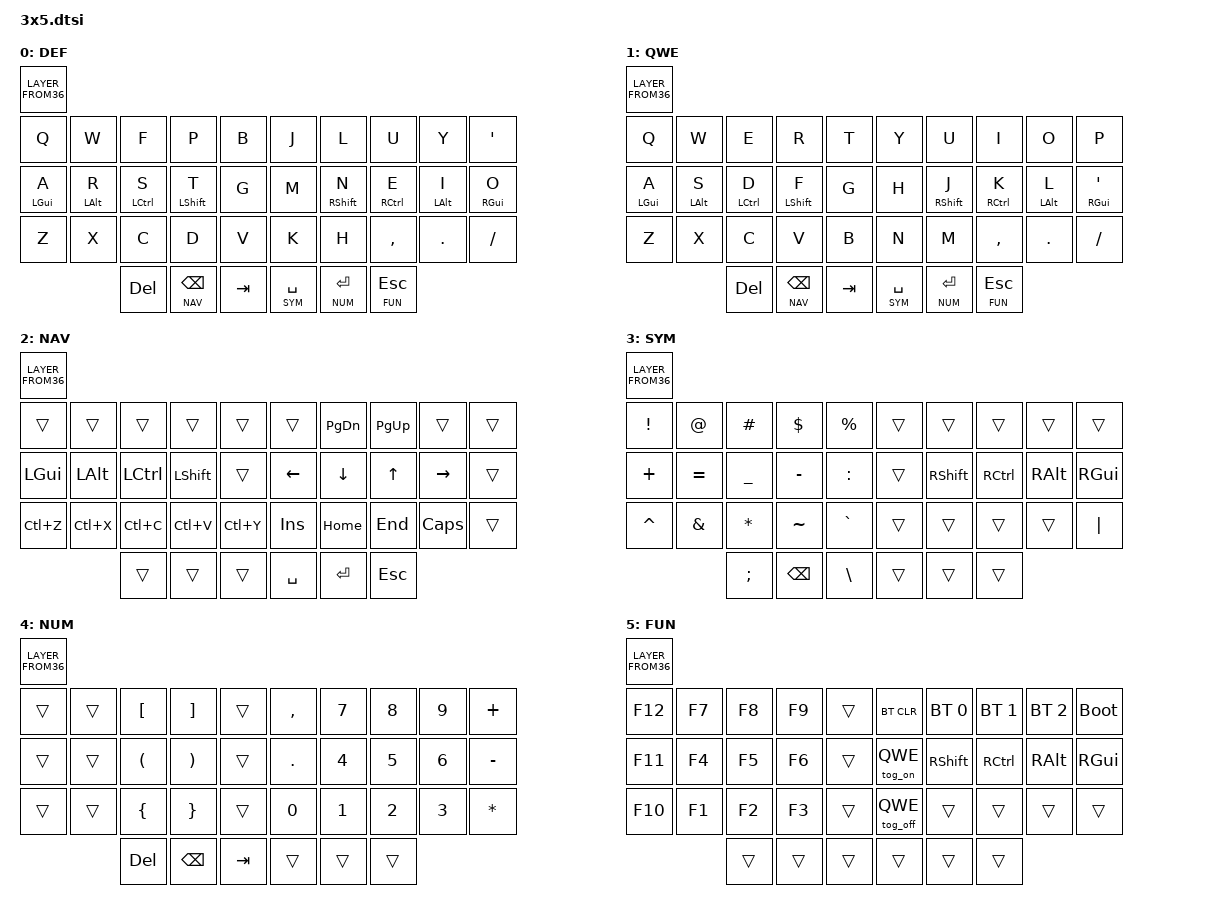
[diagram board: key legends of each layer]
#include <behaviors.dtsi>
#include <dt-bindings/zmk/bt.h>
#include <dt-bindings/zmk/keys.h>  
#include <dt-bindings/zmk/bt.h>
#include <dt-bindings/zmk/outputs.h>

// #include "combos.dtsi"
// #include "mouse.dtsi"

#define DEF 0
#define QWE 1
#define NAV 2
#define SYM 3
#define NUM 4
#define FUN 5   

#define XXX &none
#define ___ &trans

&caps_word {
    continue-list = <UNDERSCORE MINUS BSPC DEL N1 N2 N3 N4 N5 N6 N7 N8 N9 N0>;
};

/ {
  behaviors {
    hml: home_row_mods_l {
      compatible = "zmk,behavior-hold-tap";
      #binding-cells = <2>;
      tapping-term-ms = <250>;
      quick-tap-ms = <150>;
      flavor = "balanced";
      bindings = <&kp>, <&kp>;
      hold-trigger-key-positions = <KEYS_R THUMBS>;
      hold-trigger-on-release;
      require-prior-idle-ms = <175>;
    };
    hmr: home_row_mods_r {
      compatible = "zmk,behavior-hold-tap";
      #binding-cells = <2>;
      tapping-term-ms = <250>;
      quick-tap-ms = <150>;
      flavor = "balanced";
      bindings = <&kp>, <&kp>;
      hold-trigger-key-positions = <KEYS_L THUMBS>;
      hold-trigger-on-release;
      require-prior-idle-ms = <175>;
    };
    lt: layer_tap {
      display-name = "Layer-Tap";
      compatible = "zmk,behavior-hold-tap";
      #binding-cells = <2>;
      tapping-term-ms = <150>;
      flavor = "balanced"; // <- maybe tap-preferred
      bindings = <&mo>, <&kp>;
    };        
    mt: mod_tap {
      compatible = "zmk,behavior-hold-tap";
      #binding-cells = <2>;
      flavor = "hold-preferred";
      tapping-term-ms = <150>;
      bindings = <&kp>, <&kp>;
      display-name = "Mod-Tap";
    };
    tog_on: toggle_layer_on_only {
      display-name = "Toggle Layer On";
      compatible = "zmk,behavior-toggle-layer";
      #binding-cells = <1>;
      toggle-mode = "on";
    };
    tog_off: toggle_layer_off_only {
      display-name = "Toggle Layer Off";
      compatible = "zmk,behavior-toggle-layer";
      #binding-cells = <1>;
      toggle-mode = "off";
    };
  };

  keymap {
    compatible = "zmk,keymap";

    default_layer {
      display-name = "DEF";
      bindings = <LAYER_FROM36( \
// ╭─────────────┬─────────────┬─────────────┬─────────────┬─────────────╮   ╭─────────────┬─────────────┬─────────────┬─────────────┬─────────────╮
     &kp Q,        &kp W,        &kp F,        &kp P,        &kp B,            &kp J,        &kp L,        &kp U,        &kp Y,        &kp SQT,      \
// ├─────────────┼─────────────┼─────────────┼─────────────┼─────────────┤   ├─────────────┼─────────────┼─────────────┼─────────────┼─────────────┤
     &hml LGUI A,  &hml LALT R,  &hml LCTRL S, &hml LSHFT T, &kp G,            &kp M,        &hmr RSHFT N, &hmr RCTRL E, &hmr LALT I,  &hmr RGUI O,  \
// ├─────────────┼─────────────┼─────────────┼─────────────┼─────────────┤   ├─────────────┼─────────────┼─────────────┼─────────────┼─────────────┤
     &kp Z,        &kp X,        &kp C,        &kp D,        &kp V,            &kp K,        &kp H,        &kp COMMA,    &kp DOT,      &kp SLASH,    \
// ╰─────────────┴─────────────┴─────────────┼─────────────┼─────────────┤   ├─────────────┼─────────────┼─────────────┴─────────────┴─────────────╯
                                 &kp DEL,      &lt NAV BSPC, &kp TAB,          &lt SYM SPACE,&lt NUM RET,  &lt FUN ESC  
//                             ╰─────────────┴─────────────┴─────────────╯   ╰─────────────┴─────────────┴─────────────╯
      )>;
    };

    qwerty_layer {
      display-name = "QWE";
      bindings = <LAYER_FROM36( \
// ╭─────────────┬─────────────┬─────────────┬─────────────┬─────────────╮   ╭─────────────┬─────────────┬─────────────┬─────────────┬─────────────╮
     &kp Q,        &kp W,        &kp E,        &kp R,        &kp T,            &kp Y,        &kp U,        &kp I,        &kp O,        &kp P,        \
// ├─────────────┼─────────────┼─────────────┼─────────────┼─────────────┤   ├─────────────┼─────────────┼─────────────┼─────────────┼─────────────┤
     &hml LGUI A,  &hml LALT S,  &hml LCTRL D, &hml LSHFT F, &kp G,            &kp H,        &hmr RSHFT J, &hmr RCTRL K, &hmr LALT L,  &hmr RGUI SQT, \
// ├─────────────┼─────────────┼─────────────┼─────────────┼─────────────┤   ├─────────────┼─────────────┼─────────────┼─────────────┼─────────────┤
     &kp Z,        &kp X,        &kp C,        &kp V,        &kp B,            &kp N,        &kp M,        &kp COMMA,    &kp DOT,      &kp FSLH,     \
// ╰─────────────┴─────────────┴─────────────┼─────────────┼─────────────┤   ├─────────────┼─────────────┼─────────────┴─────────────┴─────────────╯
                                 &kp DEL,      &lt NAV BSPC, &kp TAB,          &lt SYM SPACE,&lt NUM RET,  &lt FUN ESC  
//                             ╰─────────────┴─────────────┴─────────────╯   ╰─────────────┴─────────────┴─────────────╯
      )>;      
    };

    nav_layer {
      display-name = "NAV";
      bindings = <LAYER_FROM36( \
// ╭─────────────┬─────────────┬─────────────┬─────────────┬─────────────╮   ╭─────────────┬─────────────┬─────────────┬─────────────┬─────────────╮
     ___,          ___,          ___,          ___,          ___,              ___,          &kp PG_DN,    &kp PG_UP,    ___,          ___,          \
// ├─────────────┼─────────────┼─────────────┼─────────────┼─────────────┤   ├─────────────┼─────────────┼─────────────┼─────────────┼─────────────┤
     &kp LGUI,     &kp LALT,     &kp LCTRL,    &kp LSHFT,    ___,              &kp LEFT,     &kp DOWN,     &kp UP,       &kp RIGHT,    ___,          \
// ├─────────────┼─────────────┼─────────────┼─────────────┼─────────────┤   ├─────────────┼─────────────┼─────────────┼─────────────┼─────────────┤
     &kp LC(Z),    &kp LC(X),    &kp LC(C),    &kp LC(V),    &kp LC(Y),        &kp INS,      &kp HOME,     &kp END,      &kp CAPS,     ___,          \
// ╰─────────────┴─────────────┴─────────────┼─────────────┼─────────────┤   ├─────────────┼─────────────┼─────────────┴─────────────┴─────────────╯
                                 ___,          ___,          ___,              &kp SPACE,    &kp RET,      &kp ESC
//                             ╰─────────────┴─────────────┴─────────────╯   ╰─────────────┴─────────────┴─────────────╯
      )>;
    };

    symbol_layer {
      display-name = "SYM";
      bindings = <LAYER_FROM36( \
// ╭─────────────┬─────────────┬─────────────┬─────────────┬─────────────╮   ╭─────────────┬─────────────┬─────────────┬─────────────┬─────────────╮
     &kp EXCL,     &kp AT,       &kp HASH,     &kp DLLR,     &kp PRCNT,        ___,          ___,          ___,          ___,          ___,          \
// ├─────────────┼─────────────┼─────────────┼─────────────┼─────────────┤   ├─────────────┼─────────────┼─────────────┼─────────────┼─────────────┤
     &kp PLUS,     &kp EQUAL,    &kp UNDER,    &kp MINUS,    &kp COLON,        ___,          &kp RSHFT,    &kp RCTRL,    &kp RALT,     &kp RGUI,     \
// ├─────────────┼─────────────┼─────────────┼─────────────┼─────────────┤   ├─────────────┼─────────────┼─────────────┼─────────────┼─────────────┤
     &kp CARET,    &kp AMPS,     &kp STAR,     &kp TILDE,    &kp GRAVE,        ___,          ___,          ___,          ___,          &kp PIPE,     \
// ╰─────────────┴─────────────┴─────────────┼─────────────┼─────────────┤   ├─────────────┼─────────────┼─────────────┴─────────────┴─────────────╯
                                 &kp SEMI,     &kp BSPC,     &kp BSLH,         ___,          ___,          ___
//                             ╰─────────────┴─────────────┴─────────────╯   ╰─────────────┴─────────────┴─────────────╯
      )>;
    };

    num_layer {
      display-name = "NUM";
      bindings = <LAYER_FROM36( \
// ╭─────────────┬─────────────┬─────────────┬─────────────┬─────────────╮   ╭─────────────┬─────────────┬─────────────┬─────────────┬─────────────╮
     ___,          ___,          &kp LBKT,     &kp RBKT,     ___,              &kp COMMA,    &kp N7,       &kp N8,       &kp N9,       &kp PLUS,     \
// ├─────────────┼─────────────┼─────────────┼─────────────┼─────────────┤   ├─────────────┼─────────────┼─────────────┼─────────────┼─────────────┤
     ___,          ___,          &kp LPAR,     &kp RPAR,     ___,              &kp DOT,      &kp N4,       &kp N5,       &kp N6,       &kp MINUS,    \
// ├─────────────┼─────────────┼─────────────┼─────────────┼─────────────┤   ├─────────────┼─────────────┼─────────────┼─────────────┼─────────────┤
     ___,          ___,          &kp LBRC,     &kp RBRC,     ___,              &kp N0,       &kp N1,       &kp N2,       &kp N3,       &kp STAR,     \
// ╰─────────────┴─────────────┴─────────────┼─────────────┼─────────────┤   ├─────────────┼─────────────┼─────────────┴─────────────┴─────────────╯
                                 &kp DEL,      &kp BSPC,     &kp TAB,          ___,          ___,          ___
//                             ╰─────────────┴─────────────┴─────────────╯   ╰─────────────┴─────────────┴─────────────╯
      )>;
    };

    fun_layer {
      display-name = "FUN";
      bindings = <LAYER_FROM36( \
// ╭─────────────┬─────────────┬─────────────┬─────────────┬─────────────╮   ╭─────────────┬─────────────┬─────────────┬─────────────┬─────────────╮
     &kp F12,      &kp F7,       &kp F8,       &kp F9,       ___,              &bt BT_CLR,   &bt BT_SEL 0, &bt BT_SEL 1, &bt BT_SEL 2, &bootloader,  \
// ├─────────────┼─────────────┼─────────────┼─────────────┼─────────────┤   ├─────────────┼─────────────┼─────────────┼─────────────┼─────────────┤
     &kp F11,      &kp F4,       &kp F5,       &kp F6,       ___,              &tog_on QWE,  &kp RSHFT,    &kp RCTRL,    &kp RALT,     &kp RGUI,     \
// ├─────────────┼─────────────┼─────────────┼─────────────┼─────────────┤   ├─────────────┼─────────────┼─────────────┼─────────────┼─────────────┤
     &kp F10,      &kp F1,       &kp F2,       &kp F3,       ___,              &tog_off QWE, ___,          ___,          ___,          ___,          \
// ╰─────────────┴─────────────┴─────────────┼─────────────┼─────────────┤   ├─────────────┼─────────────┼─────────────┴─────────────┴─────────────╯
                                 ___,          ___,          ___,              ___,          ___,          ___
//                             ╰─────────────┴─────────────┴─────────────╯   ╰─────────────┴─────────────┴─────────────╯
      )>;
    };
  };
};
